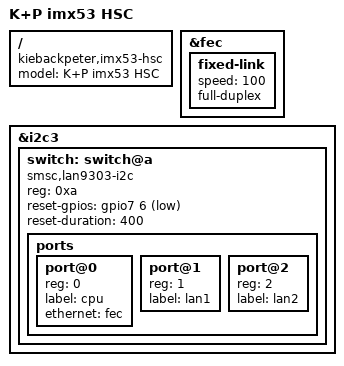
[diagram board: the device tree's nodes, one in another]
/dts-v1/;
#include "imx53-kp.dtsi"
/ {
	model = "K+P imx53 HSC";
	compatible = "kiebackpeter,imx53-hsc", "fsl,imx53";
};
&fec {
	status = "okay";
	fixed-link {  
		speed = <100>;
		full-duplex;
	};
};
&i2c3 {
	switch: switch@a {
		compatible = "smsc,lan9303-i2c";
		reg = <0xa>;
		reset-gpios = <&gpio7 6 GPIO_ACTIVE_LOW>;
		reset-duration = <400>;
		ports {
			#address-cells = <1>;
			#size-cells = <0>;
			port@0 {  
				reg = <0>;
				label = "cpu";
				ethernet = <&fec>;
			};
			port@1 {  
				reg = <1>;
				label = "lan1";
			};
			port@2 {  
				reg = <2>;
				label = "lan2";
			};
		};
	};
};
